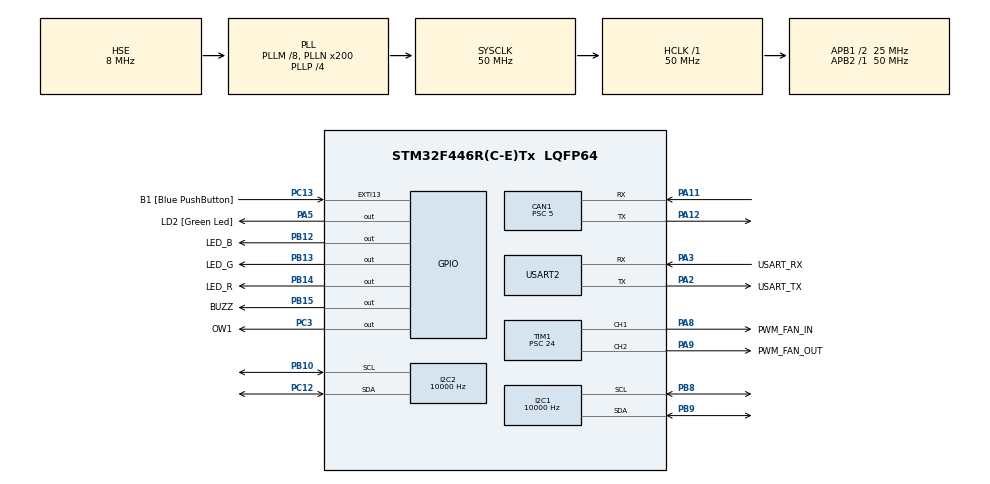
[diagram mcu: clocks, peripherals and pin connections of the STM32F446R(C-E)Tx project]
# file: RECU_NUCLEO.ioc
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CAN1.ABOM=ENABLE
CAN1.BS1=CAN_BS1_15TQ
CAN1.BS2=CAN_BS2_4TQ
CAN1.CalculateBaudRate=250000
CAN1.CalculateTimeBit=4000
CAN1.CalculateTimeQuantum=200.0
CAN1.NART=ENABLE
CAN1.Prescaler=5
CAN1.TXFP=ENABLE
I2C1.ClockSpeed=10000
I2C2.ClockSpeed=10000
IWDG.Prescaler=IWDG_PRESCALER_256
Mcu.Family=STM32F4
Mcu.Name=STM32F446R(C-E)Tx
Mcu.Package=LQFP64
NVIC.CAN1_RX0_IRQn=true\:0\:0\:false\:false\:true\:true\:true\:true
NVIC.CAN1_RX1_IRQn=true\:0\:0\:false\:false\:true\:true\:true\:true
NVIC.CAN1_TX_IRQn=true\:0\:0\:false\:false\:true\:true\:true\:true
NVIC.I2C1_EV_IRQn=true\:0\:0\:false\:false\:true\:true\:true\:true
NVIC.I2C2_EV_IRQn=true\:0\:0\:false\:false\:true\:true\:true\:true
NVIC.PriorityGroup=NVIC_PRIORITYGROUP_0
NVIC.TIM6_DAC_IRQn=true\:0\:0\:false\:false\:true\:true\:true\:true
PA11.Mode=CAN_Activate
PA11.Signal=CAN1_RX
PA12.Mode=CAN_Activate
PA12.Signal=CAN1_TX
PA13.GPIO_Label=TMS
PA13.Mode=Serial_Wire
PA13.Signal=SYS_JTMS-SWDIO
PA14.GPIO_Label=TCK
PA14.Mode=Serial_Wire
PA14.Signal=SYS_JTCK-SWCLK
PA2.GPIO_Label=USART_TX
PA2.Mode=Asynchronous
PA2.Signal=USART2_TX
PA3.GPIO_Label=USART_RX
PA3.Mode=Asynchronous
PA3.Signal=USART2_RX
PA5.GPIO_Label=LD2 [Green Led]
PA5.Signal=GPIO_Output
PA8.GPIO_Label=PWM_FAN_IN
PA8.GPIO_ModeDefaultPP=GPIO_MODE_AF_OD
PA8.GPIO_PuPd=GPIO_NOPULL
PA8.Signal=S_TIM1_CH1
PA9.GPIO_Label=PWM_FAN_OUT
PA9.GPIO_ModeDefaultPP=GPIO_MODE_AF_OD
PA9.Signal=S_TIM1_CH2
PB10.Mode=I2C
PB10.Signal=I2C2_SCL
PB12.GPIO_Label=LED_B
PB12.Signal=GPIO_Output
PB13.GPIO_Label=LED_G
PB13.Signal=GPIO_Output
PB14.GPIO_Label=LED_R
PB14.Signal=GPIO_Output
PB15.GPIO_Label=BUZZ
PB15.Signal=GPIO_Output
PB3.GPIO_Label=SWO
PB3.Signal=SYS_JTDO-SWO
PB8.Mode=I2C
PB8.Signal=I2C1_SCL
PB9.Mode=I2C
PB9.Signal=I2C1_SDA
PC12.Mode=I2C
PC12.Signal=I2C2_SDA
PC13.GPIO_Label=B1 [Blue PushButton]
PC13.GPIO_ModeDefaultEXTI=GPIO_MODE_IT_FALLING
PC13.Signal=GPXTI13
PC14-OSC32_IN.Mode=LSE-External-Oscillator
PC14-OSC32_IN.Signal=RCC_OSC32_IN
PC15-OSC32_OUT.Mode=LSE-External-Oscillator
PC15-OSC32_OUT.Signal=RCC_OSC32_OUT
PC3.GPIO_Label=OW1
PC3.GPIO_ModeDefaultOutputPP=GPIO_MODE_OUTPUT_OD
PC3.GPIO_PuPd=GPIO_NOPULL
PC3.Signal=GPIO_Output
PH0-OSC_IN.Mode=HSE-External-Oscillator
PH0-OSC_IN.Signal=RCC_OSC_IN
PH1-OSC_OUT.Mode=HSE-External-Oscillator
PH1-OSC_OUT.Signal=RCC_OSC_OUT
ProjectManager.HeapSize=0x200
ProjectManager.StackSize=0x400
ProjectManager.TargetToolchain=STM32CubeIDE
RCC.48MHZClocksFreq_Value=84000000
RCC.AHBFreq_Value=50000000
RCC.APB1CLKDivider=RCC_HCLK_DIV2
RCC.APB1Freq_Value=25000000
RCC.APB1TimFreq_Value=50000000
RCC.APB2Freq_Value=50000000
RCC.APB2TimFreq_Value=50000000
RCC.CortexFreq_Value=50000000
RCC.FLatency-AdvancedSettings=FLASH_LATENCY_1
RCC.HCLKFreq_Value=50000000
RCC.HSE_VALUE=8000000
RCC.HSI_VALUE=16000000
RCC.PLLM=8
RCC.PLLN=200
RCC.PLLP=RCC_PLLP_DIV4
RCC.PLLSourceVirtual=RCC_PLLSOURCE_HSE
RCC.RCC_RTC_Clock_SourceVirtual=RCC_RTCCLKSOURCE_HSE_DIV16
RCC.RCC_RTC_Clock_Source_FROM_HSE=RCC_RTCCLKSOURCE_HSE_DIV16
RCC.SYSCLKFreq_VALUE=50000000
RCC.SYSCLKSource=RCC_SYSCLKSOURCE_PLLCLK
RCC.USBFreq_Value=100000000
RCC.VCOOutputFreq_Value=200000000
RTC.AsynchPrediv=124
RTC.SynchPrediv=3999
SH.S_TIM1_CH1.0=TIM1_CH1,PWM Generation1 CH1
SH.S_TIM1_CH2.0=TIM1_CH2,PWM Generation2 CH2
TIM1.Channel-PWM\ Generation1\ CH1=TIM_CHANNEL_1
TIM1.Channel-PWM\ Generation2\ CH2=TIM_CHANNEL_2
TIM1.Period=1000
TIM1.Prescaler=24
TIM1.Pulse-PWM\ Generation1\ CH1=200
TIM1.Pulse-PWM\ Generation2\ CH2=200
TIM6.Period=1000
TIM6.Prescaler=4
USART2.VirtualMode=VM_ASYNC
VP_IWDG_VS_IWDG.Mode=IWDG_Activate
VP_RTC_VS_RTC_Activate.Mode=RTC_Enabled
VP_RTC_VS_RTC_Calendar.Mode=RTC_Calendar
VP_TIM1_VS_ClockSourceINT.Mode=Internal
VP_TIM6_VS_ClockSourceINT.Mode=Enable_Timer
board=NUCLEO-F446RE

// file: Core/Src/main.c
/* USER CODE BEGIN Header */
/**
  ******************************************************************************
  * @file           : main.c
  * @brief          : Main program body
  ******************************************************************************
  * @attention
  *
  * Copyright (c) 2022 STMicroelectronics.
  * All rights reserved.
  *
  * This software is licensed under terms that can be found in the LICENSE file
  * in the root directory of this software component.
  * If no LICENSE file comes with this software, it is provided AS-IS.
  *
  ******************************************************************************
  */
/* USER CODE END Header */
#include "main.h"

/* USER CODE BEGIN Includes */

#include "APP.h"
#include "MEMORY_MAP.h"
/* USER CODE END Includes */

 CAN_HandleTypeDef hcan1;

I2C_HandleTypeDef hi2c1;
I2C_HandleTypeDef hi2c2;

IWDG_HandleTypeDef hiwdg;

RTC_HandleTypeDef hrtc;

TIM_HandleTypeDef htim1;
TIM_HandleTypeDef htim6;

UART_HandleTypeDef huart2;

void SystemClock_Config(void);
static void MX_GPIO_Init(void);
static void MX_TIM1_Init(void);
static void MX_USART2_UART_Init(void);
static void MX_CAN1_Init(void);
static void MX_I2C1_Init(void);
static void MX_TIM6_Init(void);
static void MX_IWDG_Init(void);
static void MX_RTC_Init(void);
static void MX_I2C2_Init(void);

int main(void)
{
  /* USER CODE BEGIN 1 */
  SCB->VTOR = ADDRESS_OF_DEFAULT_APP_START;
  __DSB();
  __ISB();
  __enable_irq();   // clears PRIMASK

  /* USER CODE END 1 */

  /* MCU Configuration--------------------------------------------------------*/

  /* Reset of all peripherals, Initializes the Flash interface and the Systick. */
  HAL_Init();

  /* Configure the system clock */
  SystemClock_Config();

  /* Initialize all configured peripherals */
  MX_GPIO_Init();
  MX_TIM1_Init();
  MX_USART2_UART_Init();
  MX_CAN1_Init();
  MX_I2C1_Init();
  MX_TIM6_Init();
  MX_IWDG_Init();
  MX_RTC_Init();
  MX_I2C2_Init();

  /* Infinite loop */
  /* USER CODE BEGIN WHILE */

 // HAL_TIM_PWM_Start(&htim1, TIM_CHANNEL_1);

  APP_Init();

  APP_Start();

  while (1)
  {

     if (GPIO_PIN_RESET == HAL_GPIO_ReadPin(B1_GPIO_Port, B1_Pin))
     {

     }
    /* USER CODE END WHILE */

  }
}

void SystemClock_Config(void)
{
  RCC_OscInitTypeDef RCC_OscInitStruct = {0};
  RCC_ClkInitTypeDef RCC_ClkInitStruct = {0};

  /** Configure the main internal regulator output voltage
  */
  __HAL_RCC_PWR_CLK_ENABLE();
  __HAL_PWR_VOLTAGESCALING_CONFIG(PWR_REGULATOR_VOLTAGE_SCALE3);

  /** Initializes the RCC Oscillators according to the specified parameters
  * in the RCC_OscInitTypeDef structure.
  */
  RCC_OscInitStruct.OscillatorType = RCC_OSCILLATORTYPE_LSI|RCC_OSCILLATORTYPE_HSE;
  RCC_OscInitStruct.HSEState = RCC_HSE_ON;
  RCC_OscInitStruct.LSEState = RCC_LSE_ON;
  RCC_OscInitStruct.LSIState = RCC_LSI_ON;
  RCC_OscInitStruct.PLL.PLLState = RCC_PLL_ON;
  RCC_OscInitStruct.PLL.PLLSource = RCC_PLLSOURCE_HSE;
  RCC_OscInitStruct.PLL.PLLM = 8;
  RCC_OscInitStruct.PLL.PLLN = 200;
  RCC_OscInitStruct.PLL.PLLP = RCC_PLLP_DIV4;
  RCC_OscInitStruct.PLL.PLLQ = 2;
  RCC_OscInitStruct.PLL.PLLR = 2;
  if (HAL_RCC_OscConfig(&RCC_OscInitStruct) != HAL_OK)
  {
    Error_Handler();
  }

  /** Initializes the CPU, AHB and APB buses clocks
  */
  RCC_ClkInitStruct.ClockType = RCC_CLOCKTYPE_HCLK|RCC_CLOCKTYPE_SYSCLK
                              |RCC_CLOCKTYPE_PCLK1|RCC_CLOCKTYPE_PCLK2;
  RCC_ClkInitStruct.SYSCLKSource = RCC_SYSCLKSOURCE_PLLCLK;
  RCC_ClkInitStruct.AHBCLKDivider = RCC_SYSCLK_DIV1;
  RCC_ClkInitStruct.APB1CLKDivider = RCC_HCLK_DIV2;
  RCC_ClkInitStruct.APB2CLKDivider = RCC_HCLK_DIV1;

  if (HAL_RCC_ClockConfig(&RCC_ClkInitStruct, FLASH_LATENCY_1) != HAL_OK)
  {
    Error_Handler();
  }
}

static void MX_CAN1_Init(void)
{

  hcan1.Instance = CAN1;
  hcan1.Init.Prescaler = 5;
  hcan1.Init.Mode = CAN_MODE_NORMAL;
  hcan1.Init.SyncJumpWidth = CAN_SJW_1TQ;
  hcan1.Init.TimeSeg1 = CAN_BS1_15TQ;
  hcan1.Init.TimeSeg2 = CAN_BS2_4TQ;
  hcan1.Init.TimeTriggeredMode = DISABLE;
  hcan1.Init.AutoBusOff = ENABLE;
  hcan1.Init.AutoWakeUp = DISABLE;
  hcan1.Init.AutoRetransmission = ENABLE;
  hcan1.Init.ReceiveFifoLocked = DISABLE;
  hcan1.Init.TransmitFifoPriority = ENABLE;
  if (HAL_CAN_Init(&hcan1) != HAL_OK)
  {
    Error_Handler();
  }

}

static void MX_I2C1_Init(void)
{

  hi2c1.Instance = I2C1;
  hi2c1.Init.ClockSpeed = 10000;
  hi2c1.Init.DutyCycle = I2C_DUTYCYCLE_2;
  hi2c1.Init.OwnAddress1 = 0;
  hi2c1.Init.AddressingMode = I2C_ADDRESSINGMODE_7BIT;
  hi2c1.Init.DualAddressMode = I2C_DUALADDRESS_DISABLE;
  hi2c1.Init.OwnAddress2 = 0;
  hi2c1.Init.GeneralCallMode = I2C_GENERALCALL_DISABLE;
  hi2c1.Init.NoStretchMode = I2C_NOSTRETCH_DISABLE;
  if (HAL_I2C_Init(&hi2c1) != HAL_OK)
  {
    Error_Handler();
  }

}

static void MX_I2C2_Init(void)
{

  hi2c2.Instance = I2C2;
  hi2c2.Init.ClockSpeed = 10000;
  hi2c2.Init.DutyCycle = I2C_DUTYCYCLE_2;
  hi2c2.Init.OwnAddress1 = 0;
  hi2c2.Init.AddressingMode = I2C_ADDRESSINGMODE_7BIT;
  hi2c2.Init.DualAddressMode = I2C_DUALADDRESS_DISABLE;
  hi2c2.Init.OwnAddress2 = 0;
  hi2c2.Init.GeneralCallMode = I2C_GENERALCALL_DISABLE;
  hi2c2.Init.NoStretchMode = I2C_NOSTRETCH_DISABLE;
  if (HAL_I2C_Init(&hi2c2) != HAL_OK)
  {
    Error_Handler();
  }

}

static void MX_IWDG_Init(void)
{

  hiwdg.Instance = IWDG;
  hiwdg.Init.Prescaler = IWDG_PRESCALER_256;
  hiwdg.Init.Reload = 4095;
  if (HAL_IWDG_Init(&hiwdg) != HAL_OK)
  {
    Error_Handler();
  }

}

static void MX_RTC_Init(void)
{

  RTC_TimeTypeDef sTime = {0};
  RTC_DateTypeDef sDate = {0};

  /** Initialize RTC Only
  */
  hrtc.Instance = RTC;
  hrtc.Init.HourFormat = RTC_HOURFORMAT_24;
  hrtc.Init.AsynchPrediv = 124;
  hrtc.Init.SynchPrediv = 3999;
  hrtc.Init.OutPut = RTC_OUTPUT_DISABLE;
  hrtc.Init.OutPutPolarity = RTC_OUTPUT_POLARITY_HIGH;
  hrtc.Init.OutPutType = RTC_OUTPUT_TYPE_OPENDRAIN;
  if (HAL_RTC_Init(&hrtc) != HAL_OK)
  {
    Error_Handler();
  }

  /** Initialize RTC and set the Time and Date
  */
  sTime.Hours = 0x0;
  sTime.Minutes = 0x0;
  sTime.Seconds = 0x0;
  sTime.DayLightSaving = RTC_DAYLIGHTSAVING_NONE;
  sTime.StoreOperation = RTC_STOREOPERATION_RESET;
  if (HAL_RTC_SetTime(&hrtc, &sTime, RTC_FORMAT_BCD) != HAL_OK)
  {
    Error_Handler();
  }
  sDate.WeekDay = RTC_WEEKDAY_MONDAY;
  sDate.Month = RTC_MONTH_JANUARY;
  sDate.Date = 0x1;
  sDate.Year = 0x0;

  if (HAL_RTC_SetDate(&hrtc, &sDate, RTC_FORMAT_BCD) != HAL_OK)
  {
    Error_Handler();
  }

}

static void MX_TIM1_Init(void)
{

  TIM_ClockConfigTypeDef sClockSourceConfig = {0};
  TIM_MasterConfigTypeDef sMasterConfig = {0};
  TIM_OC_InitTypeDef sConfigOC = {0};
  TIM_BreakDeadTimeConfigTypeDef sBreakDeadTimeConfig = {0};

  htim1.Instance = TIM1;
  htim1.Init.Prescaler = 24;
  htim1.Init.CounterMode = TIM_COUNTERMODE_UP;
  htim1.Init.Period = 1000;
  htim1.Init.ClockDivision = TIM_CLOCKDIVISION_DIV1;
  htim1.Init.RepetitionCounter = 0;
  htim1.Init.AutoReloadPreload = TIM_AUTORELOAD_PRELOAD_DISABLE;
  if (HAL_TIM_Base_Init(&htim1) != HAL_OK)
  {
    Error_Handler();
  }
  sClockSourceConfig.ClockSource = TIM_CLOCKSOURCE_INTERNAL;
  if (HAL_TIM_ConfigClockSource(&htim1, &sClockSourceConfig) != HAL_OK)
  {
    Error_Handler();
  }
  if (HAL_TIM_PWM_Init(&htim1) != HAL_OK)
  {
    Error_Handler();
  }
  sMasterConfig.MasterOutputTrigger = TIM_TRGO_RESET;
  sMasterConfig.MasterSlaveMode = TIM_MASTERSLAVEMODE_DISABLE;
  if (HAL_TIMEx_MasterConfigSynchronization(&htim1, &sMasterConfig) != HAL_OK)
  {
    Error_Handler();
  }
  sConfigOC.OCMode = TIM_OCMODE_PWM1;
  sConfigOC.Pulse = 200;
  sConfigOC.OCPolarity = TIM_OCPOLARITY_HIGH;
  sConfigOC.OCNPolarity = TIM_OCNPOLARITY_HIGH;
  sConfigOC.OCFastMode = TIM_OCFAST_DISABLE;
  sConfigOC.OCIdleState = TIM_OCIDLESTATE_RESET;
  sConfigOC.OCNIdleState = TIM_OCNIDLESTATE_RESET;
  if (HAL_TIM_PWM_ConfigChannel(&htim1, &sConfigOC, TIM_CHANNEL_1) != HAL_OK)
  {
    Error_Handler();
  }
  if (HAL_TIM_PWM_ConfigChannel(&htim1, &sConfigOC, TIM_CHANNEL_2) != HAL_OK)
  {
    Error_Handler();
  }
  sBreakDeadTimeConfig.OffStateRunMode = TIM_OSSR_DISABLE;
  sBreakDeadTimeConfig.OffStateIDLEMode = TIM_OSSI_DISABLE;
  sBreakDeadTimeConfig.LockLevel = TIM_LOCKLEVEL_OFF;
  sBreakDeadTimeConfig.DeadTime = 0;
  sBreakDeadTimeConfig.BreakState = TIM_BREAK_DISABLE;
  sBreakDeadTimeConfig.BreakPolarity = TIM_BREAKPOLARITY_HIGH;
  sBreakDeadTimeConfig.AutomaticOutput = TIM_AUTOMATICOUTPUT_DISABLE;
  if (HAL_TIMEx_ConfigBreakDeadTime(&htim1, &sBreakDeadTimeConfig) != HAL_OK)
  {
    Error_Handler();
  }
  HAL_TIM_MspPostInit(&htim1);

}

static void MX_TIM6_Init(void)
{

  TIM_MasterConfigTypeDef sMasterConfig = {0};

  htim6.Instance = TIM6;
  htim6.Init.Prescaler = 4;
  htim6.Init.CounterMode = TIM_COUNTERMODE_UP;
  htim6.Init.Period = 1000;
  htim6.Init.AutoReloadPreload = TIM_AUTORELOAD_PRELOAD_DISABLE;
  if (HAL_TIM_Base_Init(&htim6) != HAL_OK)
  {
    Error_Handler();
  }
  sMasterConfig.MasterOutputTrigger = TIM_TRGO_RESET;
  sMasterConfig.MasterSlaveMode = TIM_MASTERSLAVEMODE_DISABLE;
  if (HAL_TIMEx_MasterConfigSynchronization(&htim6, &sMasterConfig) != HAL_OK)
  {
    Error_Handler();
  }

}

static void MX_USART2_UART_Init(void)
{

  huart2.Instance = USART2;
  huart2.Init.BaudRate = 115200;
  huart2.Init.WordLength = UART_WORDLENGTH_8B;
  huart2.Init.StopBits = UART_STOPBITS_1;
  huart2.Init.Parity = UART_PARITY_NONE;
  huart2.Init.Mode = UART_MODE_TX_RX;
  huart2.Init.HwFlowCtl = UART_HWCONTROL_NONE;
  huart2.Init.OverSampling = UART_OVERSAMPLING_16;
  if (HAL_UART_Init(&huart2) != HAL_OK)
  {
    Error_Handler();
  }

}

static void MX_GPIO_Init(void)
{
  GPIO_InitTypeDef GPIO_InitStruct = {0};

  /* GPIO Ports Clock Enable */
  __HAL_RCC_GPIOC_CLK_ENABLE();
  __HAL_RCC_GPIOH_CLK_ENABLE();
  __HAL_RCC_GPIOA_CLK_ENABLE();
  __HAL_RCC_GPIOB_CLK_ENABLE();

  /*Configure GPIO pin Output Level */
  HAL_GPIO_WritePin(OW1_GPIO_Port, OW1_Pin, GPIO_PIN_RESET);

  /*Configure GPIO pin Output Level */
  HAL_GPIO_WritePin(LD2_GPIO_Port, LD2_Pin, GPIO_PIN_RESET);

  /*Configure GPIO pin Output Level */
  HAL_GPIO_WritePin(GPIOB, LED_B_Pin|LED_G_Pin|LED_R_Pin|BUZZ_Pin, GPIO_PIN_RESET);

  /*Configure GPIO pin : B1_Pin */
  GPIO_InitStruct.Pin = B1_Pin;
  GPIO_InitStruct.Mode = GPIO_MODE_IT_FALLING;
  GPIO_InitStruct.Pull = GPIO_NOPULL;
  HAL_GPIO_Init(B1_GPIO_Port, &GPIO_InitStruct);

  /*Configure GPIO pin : OW1_Pin */
  GPIO_InitStruct.Pin = OW1_Pin;
  GPIO_InitStruct.Mode = GPIO_MODE_OUTPUT_OD;
  GPIO_InitStruct.Pull = GPIO_NOPULL;
  GPIO_InitStruct.Speed = GPIO_SPEED_FREQ_LOW;
  HAL_GPIO_Init(OW1_GPIO_Port, &GPIO_InitStruct);

  /*Configure GPIO pin : LD2_Pin */
  GPIO_InitStruct.Pin = LD2_Pin;
  GPIO_InitStruct.Mode = GPIO_MODE_OUTPUT_PP;
  GPIO_InitStruct.Pull = GPIO_NOPULL;
  GPIO_InitStruct.Speed = GPIO_SPEED_FREQ_LOW;
  HAL_GPIO_Init(LD2_GPIO_Port, &GPIO_InitStruct);

  /*Configure GPIO pins : LED_B_Pin LED_G_Pin LED_R_Pin BUZZ_Pin */
  GPIO_InitStruct.Pin = LED_B_Pin|LED_G_Pin|LED_R_Pin|BUZZ_Pin;
  GPIO_InitStruct.Mode = GPIO_MODE_OUTPUT_PP;
  GPIO_InitStruct.Pull = GPIO_NOPULL;
  GPIO_InitStruct.Speed = GPIO_SPEED_FREQ_LOW;
  HAL_GPIO_Init(GPIOB, &GPIO_InitStruct);

}

void Error_Handler(void)
{
  __disable_irq();
  while (1)
  {
  }
}
